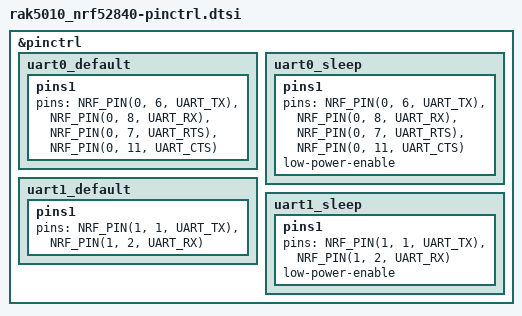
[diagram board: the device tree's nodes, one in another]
/*
 * Copyright (c) 2021 Nordic Semiconductor ASA
 * SPDX-License-Identifier: Apache-2.0
 */

&pinctrl {
	uart0_default: uart0_default {
		pins1 {
			pins = <NRF_PIN(0, 6, UART_TX)>,
			       <NRF_PIN(0, 8, UART_RX)>,
			       <NRF_PIN(0, 7, UART_RTS)>,
			       <NRF_PIN(0, 11, UART_CTS)>;
		};
	};

	uart0_sleep: uart0_sleep {
		pins1 {
			pins = <NRF_PIN(0, 6, UART_TX)>,
			       <NRF_PIN(0, 8, UART_RX)>,
			       <NRF_PIN(0, 7, UART_RTS)>,
			       <NRF_PIN(0, 11, UART_CTS)>;
			low-power-enable;
		};
	};

	uart1_default: uart1_default {
		pins1 {
			pins = <NRF_PIN(1, 1, UART_TX)>,
			       <NRF_PIN(1, 2, UART_RX)>;
		};
	};

	uart1_sleep: uart1_sleep {
		pins1 {
			pins = <NRF_PIN(1, 1, UART_TX)>,
			       <NRF_PIN(1, 2, UART_RX)>;
			low-power-enable;
		};
	};

};
